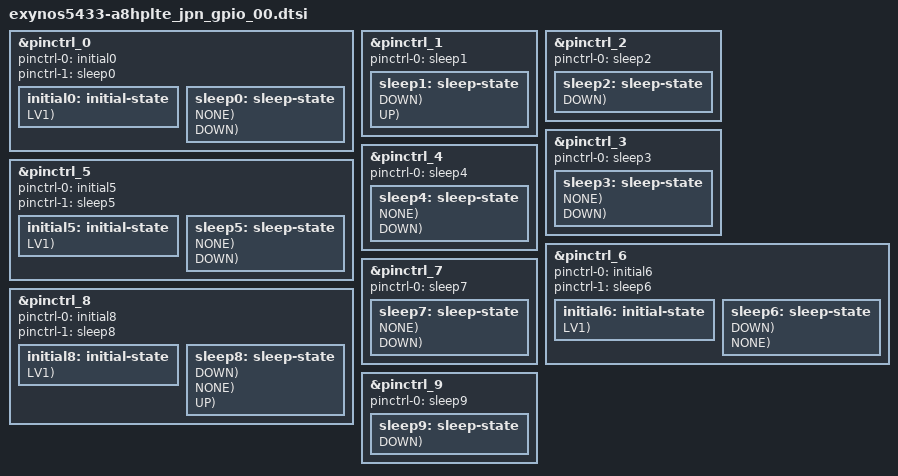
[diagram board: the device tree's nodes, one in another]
/*
 * Copyright (c) 2014 Samsung Electronics Co., Ltd.
 *		http://www.samsung.com
 *
 * This program is free software; you can redistribute it and/or modify
 * it under the terms of the GNU General Public License version 2 as
 * published by the Free Software Foundation.
*/

// Support A8 VE JPN LTE HW REV00

#include "exynos_gpio_config_macros.dtsi"

&pinctrl_0 {
	pinctrl-names = "default","sleep";
	pinctrl-0 = <&initial0>;
	pinctrl-1 = <&sleep0>;

	initial0: initial-state {
		PIN_IN(gpa0-0, NONE, LV1);	/* EAR_ANT_DET */
		PIN_IN(gpa1-2, DOWN, LV1);	/* NC */
		PIN_IN(gpa1-4, NONE, LV1);	/* 3_4_POLE_DET */

		PIN_IN(gpf1-0, DOWN, LV1);	/* NC */

		PIN_IN(gpf5-0, DOWN, LV1);	/* NC */
	};
	sleep0: sleep-state {
		PIN_SLP(gpa0-0, INPUT, NONE);	/* EAR_ANT_DET */
		PIN_SLP(gpa0-6, INPUT, DOWN);	/* OVP_EN */

		PIN_SLP(gpa1-4, INPUT, NONE);	/* 3_4_POLE_DET */

		PIN_SLP(gpf1-0, INPUT, DOWN);	/* NC */
		PIN_SLP(gpf1-1, INPUT, DOWN);	/* NC */
		PIN_SLP(gpf1-2, INPUT, DOWN);	/* NC */
		PIN_SLP(gpf1-3, INPUT, DOWN);	/* LCD_TE */
		PIN_SLP(gpf1-5, PREV, NONE);	/* LCD_1.6V_EN */
		PIN_SLP(gpf1-7, OUT0, DOWN);	/* ISDBT_RST */

		PIN_SLP(gpf2-0, INPUT, DOWN);	/* BTP_CHECK */
		PIN_SLP(gpf2-1, PREV, NONE);	/* CODEC_RESET_N */
		PIN_SLP(gpf2-2, INPUT, DOWN);	/* AMP_RST */
		PIN_SLP(gpf2-3, INPUT, DOWN);	/* NC */

		PIN_SLP(gpf3-0, INPUT, DOWN);	/* NC */
		PIN_SLP(gpf3-1, INPUT, DOWN);	/* NC */
		PIN_SLP(gpf3-2, INPUT, DOWN);	/* NC */
		PIN_SLP(gpf3-3, INPUT, DOWN);	/* NC */

		PIN_SLP(gpf4-0, PREV, DOWN);	/* BTP_LDO_EN */
		PIN_SLP(gpf4-1, INPUT, DOWN);	/* NC */
		PIN_SLP(gpf4-2, INPUT, DOWN);	/* NC */
		PIN_SLP(gpf4-3, PREV, NONE);	/* AP_CP_STATUS */
		PIN_SLP(gpf4-4, OUT0, NONE);	/* AP_CP_DUMP_NOTI_N */
		PIN_SLP(gpf4-5, PREV, NONE);	/* AP_CP_PACKET_SEND */
		PIN_SLP(gpf4-6, PREV, NONE);	/* AP_CP_WAKE */
		PIN_SLP(gpf4-7, INPUT, DOWN);	/* AP_CP_GPIO_RSV - NC */

		PIN_SLP(gpf5-0, INPUT, DOWN);	/* NC */
		PIN_SLP(gpf5-1, INPUT, DOWN);	/* NC */
		PIN_SLP(gpf5-2, PREV, DOWN);	/* BTP_RST_N */
		PIN_SLP(gpf5-3, INPUT, DOWN);	/* NC */
		PIN_SLP(gpf5-4, OUT1, NONE);	/* WRSTB_IN */
		PIN_SLP(gpf5-5, INPUT, DOWN);	/* EL_ON1_DET */
		PIN_SLP(gpf5-6, OUT0, DOWN);	/* ISDBT_PWR_EN */
		PIN_SLP(gpf5-7, INPUT, DOWN);	/* NC */
	};
};

&pinctrl_1 {
	pinctrl-names = "sleep";
	pinctrl-0 = <&sleep1>;
	sleep1: sleep-state {
		PIN_SLP(gpz0-0, INPUT, DOWN);	/* MM_I2S_CLK */
		PIN_SLP(gpz0-1, INPUT, DOWN);	/* NC */
		PIN_SLP(gpz0-2, INPUT, DOWN);	/* MM_I2S_SYNC */
		PIN_SLP(gpz0-3, INPUT, DOWN);	/* MM_I2S_DI */
		PIN_SLP(gpz0-4, INPUT, DOWN);	/* MM_I2S_DO */
		PIN_SLP(gpz0-5, INPUT, DOWN);	/* NC */
		PIN_SLP(gpz0-6, INPUT, DOWN);	/* NC */

		PIN_SLP(gpz1-0, OUT1, UP);	/* BT_UART_TXD */
		PIN_SLP(gpz1-1, INPUT, UP);	/* BT_UART_RXD */
		PIN_SLP(gpz1-2, INPUT, UP);	/* BT_UART_CTS */
		PIN_SLP(gpz1-3, OUT1, UP);	/* BT_UART_RTS */
	};
};

&pinctrl_2 {
	pinctrl-names = "sleep";
	pinctrl-0 = <&sleep2>;
	sleep2: sleep-state {
		PIN_SLP(gpv6-0, INPUT, DOWN);	/* NC */
		PIN_SLP(gpv6-1, INPUT, DOWN);	/* NC */
	};
};

&pinctrl_3 {
	pinctrl-names = "sleep";
	pinctrl-0 = <&sleep3>;
	sleep3: sleep-state {
		PIN_SLP(gpj2-0, PREV, NONE);	/* WLAN_EN */
		PIN_SLP(gpj2-1, OUT0, DOWN);	/* GPS_EN */
		PIN_SLP(gpj2-2, INPUT, DOWN);	/* FACTORY_DISCHG */
	};
};

&pinctrl_4 {
	pinctrl-names = "sleep";
	pinctrl-0 = <&sleep4>;
	sleep4: sleep-state {
		PIN_SLP(gpd5-0, OUT0, NONE);	/* BTP_SPI_CLK */
		PIN_SLP(gpd5-1, OUT0, NONE);	/* BTP_SPI_CS_N */
		PIN_SLP(gpd5-2, INPUT, DOWN);	/* BTP_SPI_MISO */
		PIN_SLP(gpd5-3, OUT0, NONE);	/* BTP_SPI_MOSI */
	};
};

&pinctrl_5 {
	pinctrl-names = "default","sleep";
	pinctrl-0 = <&initial5>;
	pinctrl-1 = <&sleep5>;
	initial5: initial-state {
		PIN_IN(gph1-0, NONE, LV1);	/* VDD_1P8_AP 10K PU */
		PIN_IN(gph1-1, DOWN, LV1);	/* NC */
		PIN_IN(gph1-2, NONE, LV1);	/* VDD_1P8_AP 10K PU */
		PIN_IN(gph1-3, DOWN, LV1);	/* NC */
		PIN_IN(gph1-4, DOWN, LV1);	/* NC */
		PIN_IN(gph1-5, DOWN, LV1);	/* NC */

		PIN_IN(gpr3-5, DOWN, LV1);	/* NC */
		PIN_IN(gpr3-6, DOWN, LV1);	/* NC */
		PIN_IN(gpr3-7, DOWN, LV1);	/* NC */

		PIN_IN(gpr4-2, DOWN, LV1);	/* NC */

		PIN_IN(gpr0-3, DOWN, LV1);	/* NC */
		PIN_IN(gpr0-4, DOWN, LV1);	/* NC */
	};
	sleep5: sleep-state {
		PIN_SLP(gph1-0, INPUT, NONE);	/* VDD_1.8_AP P/U */
		PIN_SLP(gph1-1, INPUT, DOWN);	/* NC */
		PIN_SLP(gph1-2, INPUT, NONE);	/* VDD_1.8_AP P/U */
		PIN_SLP(gph1-3, INPUT, DOWN);	/* NC */
		PIN_SLP(gph1-4, INPUT, DOWN);	/* NC */
		PIN_SLP(gph1-5, INPUT, DOWN);	/* NC */

		PIN_SLP(gpr4-0, INPUT, DOWN);	/* T_FLASH_CLK */
		PIN_SLP(gpr4-1, INPUT, DOWN);	/* T_FLASH_CMD */
		PIN_SLP(gpr4-2, INPUT, DOWN);	/* NC */
		PIN_SLP(gpr4-3, INPUT, DOWN);	/* T_FLASH_D(0) */
		PIN_SLP(gpr4-4, INPUT, DOWN);	/* T_FLASH_D(1) */
		PIN_SLP(gpr4-5, INPUT, DOWN);	/* T_FLASH_D(2) */
		PIN_SLP(gpr4-6, INPUT, DOWN);	/* T_FLASH_D(3) */

		PIN_SLP(gpr0-0, INPUT, DOWN);	/* NC */
		PIN_SLP(gpr0-1, INPUT, NONE);	/* MEM_1P8 P/U */
		PIN_SLP(gpr0-2, INPUT, DOWN);	/* PD GND */
		PIN_SLP(gpr0-3, INPUT, DOWN);	/* NC */
		PIN_SLP(gpr0-4, INPUT, DOWN);	/* NC */

		PIN_SLP(gpr1-0, INPUT, NONE);	/* MEM_VDD_1.8V */
		PIN_SLP(gpr1-1, INPUT, NONE);	/* MEM_VDD_1.8V */
		PIN_SLP(gpr1-2, INPUT, NONE);	/* MEM_VDD_1.8V */
		PIN_SLP(gpr1-3, INPUT, NONE);	/* MEM_VDD_1.8V */
		PIN_SLP(gpr1-4, INPUT, NONE);	/* MEM_VDD_1.8V */
		PIN_SLP(gpr1-5, INPUT, NONE);	/* MEM_VDD_1.8V */
		PIN_SLP(gpr1-6, INPUT, NONE);	/* MEM_VDD_1.8V */
		PIN_SLP(gpr1-7, INPUT, NONE);	/* MEM_VDD_1.8V */

		PIN_SLP(gpr2-0, OUT0, NONE);	/* WLAN_CLK */
		PIN_SLP(gpr2-1, INPUT, NONE);	/* WLAN_CMD */

		PIN_SLP(gpr3-0, INPUT, NONE);	/* WLAN_D(0) */
		PIN_SLP(gpr3-1, INPUT, NONE);	/* WLAN_D(1) */
		PIN_SLP(gpr3-2, INPUT, NONE);	/* WLAN_D(2) */
		PIN_SLP(gpr3-3, INPUT, NONE);	/* WLAN_D(3) */
		PIN_SLP(gpr3-4, PREV, NONE);	/* BUCK6_DVS */
		PIN_SLP(gpr3-5, INPUT, DOWN);	/* NC */
		PIN_SLP(gpr3-6, INPUT, DOWN);	/* NC */
		PIN_SLP(gpr3-7, INPUT, DOWN);	/* NC */
	};
};

&pinctrl_6 {
	pinctrl-names = "default","sleep";
	pinctrl-0 = <&initial6>;
	pinctrl-1 = <&sleep6>;
	initial6: initial-state {
		PIN_IN(gpf0-0, DOWN, LV1);	/* NC */
		PIN_IN(gpf0-2, DOWN, LV1);	/* NC */
		PIN_IN(gpf0-3, DOWN, LV1);	/* NC */
		PIN_IN(gpf0-4, DOWN, LV1);	/* NC */
		PIN_IN(gpf0-5, DOWN, LV1);	/* NC */
		PIN_IN(gpf0-6, DOWN, LV1);	/* NC */
	};
	sleep6: sleep-state {
		PIN_SLP(gpf0-0, INPUT, DOWN);	/* NC */
		PIN_SLP(gpf0-1, OUT0, NONE);	/* BUCK6EN */
		PIN_SLP(gpf0-2, INPUT, DOWN);	/* NC */
		PIN_SLP(gpf0-3, INPUT, DOWN);	/* NC */
		PIN_SLP(gpf0-4, INPUT, DOWN);	/* NC */
		PIN_SLP(gpf0-5, INPUT, DOWN);	/* NC */
		PIN_SLP(gpf0-6, INPUT, DOWN);	/* NC */
		PIN_SLP(gpf0-7, PREV, NONE);	/* LDO17_EN */
	};
};

&pinctrl_7 {
	pinctrl-names = "sleep";
	pinctrl-0 = <&sleep7>;
	sleep7: sleep-state {
		PIN_SLP(gpj0-0, INPUT, NONE);	/* SENSOR2_I2C_SDA acc */
		PIN_SLP(gpj0-1, INPUT, NONE);	/*  SENSOR2_I2C_SCL acc */
		PIN_SLP(gpj0-2, INPUT, DOWN);	/* NC */
	};
};

&pinctrl_8 {
	pinctrl-names = "default","sleep";
	pinctrl-0 = <&initial8>;
	pinctrl-1 = <&sleep8>;
	initial8: initial-state {
		PIN_IN(gpd4-3, NONE, LV1);	/* ISDBT_FELICA_SDA */
		PIN_IN(gpd4-4, NONE, LV1);	/* ISDBT_FELICA_SCL */

		PIN_IN(gpd6-0, DOWN, LV1);	/* NC */
		PIN_IN(gpd6-1, DOWN, LV1);	/* NC */

		PIN_IN(gpd8-0, DOWN, LV1);	/* NC */
		PIN_IN(gpd8-1, DOWN, LV1);	/* NC */

		PIN_IN(gpg3-4, NONE, LV1);	/* HW_REV(0) */
		PIN_IN(gpg3-5, NONE, LV1);	/* HW_REV(1) */
		PIN_IN(gpg3-6, NONE, LV1);	/* HW_REV(2) */
		PIN_IN(gpg3-7, NONE, LV1);	/* HW_REV(3) */

		PIN_IN(gpv7-5, DOWN, LV1);	/* GND 10K PD */
	};
	sleep8: sleep-state {
		PIN_SLP(gpv7-0, INPUT, DOWN);	/* NC */
		PIN_SLP(gpv7-1, INPUT, DOWN);	/* PCD_INT */
		PIN_SLP(gpv7-2, PREV, NONE);	/* MLCD_RST */
		PIN_SLP(gpv7-3, PREV, NONE);	/* CODEC_LDO_EN*/
		PIN_SLP(gpv7-4, INPUT, DOWN);	/* NC */
		PIN_SLP(gpv7-5, INPUT, DOWN);	/* NC */

		PIN_SLP(gpb0-0, INPUT, NONE);	/* SENSOR_SDA_1.8V */
		PIN_SLP(gpb0-1, INPUT, NONE);	/* SENSOR_SCL_1.8V */
		PIN_SLP(gpb0-2, INPUT, NONE);	/* TOUCH_SDA_1.8V */
		PIN_SLP(gpb0-3, INPUT, NONE);	/* TOUCH_SCL_1.8V */
		PIN_SLP(gpb0-4, INPUT, DOWN);	/* FG_ERR */

		PIN_SLP(gpc0-0, INPUT, NONE);	/* MEM_SDA_1.8V */
		PIN_SLP(gpc0-1, PREV, NONE);	/* FLASH_EN */
		PIN_SLP(gpc0-2, INPUT, DOWN);	/* SIM_PWR_SEL */
		PIN_SLP(gpc0-3, INPUT, DOWN);	/* VTCAM_RST_N */
		PIN_SLP(gpc0-4, INPUT, DOWN);	/* CAM_RST */
		PIN_SLP(gpc0-5, INPUT, DOWN);	/* CAM_LDO_EN */
		PIN_SLP(gpc0-6, INPUT, DOWN);	/* NC */
		PIN_SLP(gpc0-7, INPUT, NONE);	/* MEM_SCL_1.8V */

		PIN_SLP(gpc1-0, INPUT, DOWN);	/* NC */
		PIN_SLP(gpc1-1, INPUT, DOWN);	/* NC */

		PIN_SLP(gpc2-0, INPUT, DOWN);	/* CAM_SDA_1.8V */
		PIN_SLP(gpc2-1, INPUT, DOWN);	/* CAM_SCL_1.8V */
		PIN_SLP(gpc2-2, INPUT, DOWN);	/* CAM_EEP_SDA_1.8V */
		PIN_SLP(gpc2-3, INPUT, DOWN);	/* CAM_EEP_SDL_1.8V */
		PIN_SLP(gpc2-4, INPUT, DOWN);	/* VTCAM_SDA_1.8V */
		PIN_SLP(gpc2-5, INPUT, DOWN);	/* VTCAM_SCL_1.8V */

		PIN_SLP(gpc3-0, INPUT, DOWN);	/* NC */
		PIN_SLP(gpc3-1, INPUT, DOWN);	/* NC */
		PIN_SLP(gpc3-2, INPUT, DOWN);	/* NC */
		PIN_SLP(gpc3-3, INPUT, DOWN);	/* NC */
		PIN_SLP(gpc3-4, INPUT, DOWN);	/* CP_SPI_CLK */
		PIN_SLP(gpc3-5, OUT0, DOWN);	/* CP_SPI_CS_N */
		PIN_SLP(gpc3-6, INPUT, DOWN);	/* CP_SPI_MISO */
		PIN_SLP(gpc3-7, INPUT, DOWN);	/* CP_SPI_MOSI */

		PIN_SLP(gpg0-0, INPUT, DOWN);	/* NC */
		PIN_SLP(gpg0-1, INPUT, DOWN);	/* NC */

		PIN_SLP(gpd0-0, INPUT, UP);	/* GPS_UART_RXD */
		PIN_SLP(gpd0-1, INPUT, UP);	/* GPS_UART_TXD */
		PIN_SLP(gpd0-2, INPUT, DOWN);	/* GPS_UART_CTS */
		PIN_SLP(gpd0-3, OUT1, NONE);	/* GPS_UART_RTS */

		PIN_SLP(gpd1-4, INPUT, DOWN);	/* AP_UART_RXD */
		PIN_SLP(gpd1-5, INPUT, DOWN);	/* AP_UART_TXD */

		PIN_SLP(gpd2-0, INPUT, NONE);	/* AP_PMIC_SDA */
		PIN_SLP(gpd2-1, INPUT, NONE);	/* AP_PMIC_SCL */
		PIN_SLP(gpd2-2, INPUT, NONE);	/* IF_PMIC_SDA_1.8V */
		PIN_SLP(gpd2-3, INPUT, NONE);	/* IF_PMIC_SDL_1.8V */
		PIN_SLP(gpd2-4, OUT0, DOWN);	/* MOTOR_PWM */
		PIN_SLP(gpd2-5, INPUT, DOWN);	/* NC */
		PIN_SLP(gpd2-6, INPUT, NONE);	/* CODEC_SDA_1.8V */
		PIN_SLP(gpd2-7, INPUT, NONE);	/* CODEC_SDA_1.8V */

		PIN_SLP(gpd4-0, PREV, NONE);	/* MOTOR_EN */
		PIN_SLP(gpd4-1, INPUT, DOWN);	/* NC */
		PIN_SLP(gpd4-2, INPUT, DOWN);	/* IFC_SENSE_INT_AP */
		PIN_SLP(gpd4-3, INPUT, NONE);	/* ISDBT_FELICA_SDA */
		PIN_SLP(gpd4-4, INPUT, NONE);	/* ISDBT_FELICA_SCL */

		PIN_SLP(gpd6-0, INPUT, DOWN);	/* NC */
		PIN_SLP(gpd6-1, INPUT, DOWN);	/* NC */
		PIN_SLP(gpd6-2, OUT0, DOWN);	/* ISDBT_SPI_CLK */
		PIN_SLP(gpd6-3, OUT1, UP);	/* ISDBT_SPI_CS_N */
		PIN_SLP(gpd6-4, OUT0, DOWN);	/* ISDBT_SPI_MISO */
		PIN_SLP(gpd6-5, OUT0, DOWN);	/* ISDBT_SPI_MOSI */
		PIN_SLP(gpd6-6, PREV, NONE);	/* BOOT_LDO */

		PIN_SLP(gpd7-0, INPUT, DOWN);	/* CAM_MCLK */
		PIN_SLP(gpd7-1, INPUT, DOWN);	/* NC */
		PIN_SLP(gpd7-2, INPUT, DOWN);	/* VTCAM_MCLK */

		PIN_SLP(gpd8-0, INPUT, DOWN);	/* NC */
		PIN_SLP(gpd8-1, INPUT, DOWN);	/* NC */

		PIN_SLP(gpg1-0, INPUT, DOWN);	/* NC */
		PIN_SLP(gpg1-1, INPUT, DOWN);	/* NC */
		PIN_SLP(gpg1-2, INPUT, DOWN);	/* NC */
		PIN_SLP(gpg1-3, INPUT, DOWN);	/* NC */
		PIN_SLP(gpg1-4, PREV, DOWN);	/* BT_EN */

		PIN_SLP(gpg2-0, PREV, NONE);	/* CP_PMIC_PWR_EN */
		PIN_SLP(gpg2-1, PREV, NONE);	/* PDA_ACTIVE */

		PIN_SLP(gpg3-0, INPUT, NONE);	/* CAM_EEP_SDA_1.8V */
		PIN_SLP(gpg3-1, INPUT, NONE);	/* CAM_EEP_SCL_1.8V */
		PIN_SLP(gpg3-2, INPUT, NONE);	/* SPK_AMP_SDA_1.8V */
		PIN_SLP(gpg3-3, INPUT, NONE);	/* SPK_AMP_SDL_1.8V  */
		PIN_SLP(gpg3-4, INPUT, NONE);	/* HW_REV0 */
		PIN_SLP(gpg3-5, INPUT, NONE);	/* HW_REV1 */
		PIN_SLP(gpg3-6, INPUT, NONE);	/* HW_REV2 */
		PIN_SLP(gpg3-7, INPUT, NONE);	/* HW_REV3 */
	};
};

&pinctrl_9 {
	pinctrl-names = "sleep";
	pinctrl-0 = <&sleep9>;
	sleep9: sleep-state {
		PIN_SLP(gpj1-0, INPUT, DOWN);	/* TSP_SDA_1.8V */
		PIN_SLP(gpj1-1, INPUT, DOWN);	/* TSP_SCL_1.8V */
		PIN_SLP(gpj1-2, INPUT, DOWN);	/* NC */
	};
};

